# RP2040 register map
Vendor: Raspberry Pi; File version: 2025.06.15
CPU: CM0PLUS r0p1, little endian, 2 interrupt priority bits
Registers are 32-bit, read-write, no defined reset value unless marked. A register's access mark holds for its fields unless they carry their own. Offsets are from the block's base; [hi:lo] are bit positions; 'fields as' and 'values as' point back to an identical list; <NAME> marks a mode.

## I2C0 (part 1 of 2) — DW_apb_i2c address block List of configuration constants for the Synopsys I2C hardware (you may see references to these in I2C register header these are *fixed* values, set at hardware design time): IC_ULTRA_FAST_MODE ................ 0x0 IC_UFM_TBUF_CNT_DEFAULT ........... 0x8 IC_UFM_SCL_LOW_COUNT .............. 0x0008 IC_UFM_SCL_HIGH_COUNT ............. 0x0006 IC_TX_TL .......................... 0x0 IC_TX_CMD_BLOCK ................... 0x1 IC_HAS_DMA ........................ 0x1 IC_HAS_ASYNC_FIFO ................. 0x0 IC_SMBUS_ARP ...................... 0x0 IC_FIRST_DATA_BYTE_STATUS ......... 0x1 IC_INTR_IO ........................ 0x1 IC_MASTER_MODE .................... 0x1 IC_DEFAULT_ACK_GENERAL_CALL ....... 0x1 IC_INTR_POL ....................... 0x1 IC_OPTIONAL_SAR ................... 0x0 IC_DEFAULT_TAR_SLAVE_ADDR ......... 0x055 IC_DEFAULT_SLAVE_ADDR ............. 0x055 IC_DEFAULT_HS_SPKLEN .............. 0x1 IC_FS_SCL_HIGH_COUNT .............. 0x0006 IC_HS_SCL_LOW_COUNT ............... 0x0008 IC_DEVICE_ID_VALUE ................ 0x0 IC_10BITADDR_MASTER ............... 0x0 IC_CLK_FREQ_OPTIMIZATION .......... 0x0 IC_DEFAULT_FS_SPKLEN .............. 0x7 IC_ADD_ENCODED_PARAMS ............. 0x0 IC_DEFAULT_SDA_HOLD ............... 0x000001 IC_DEFAULT_SDA_SETUP .............. 0x64 IC_AVOID_RX_FIFO_FLUSH_ON_TX_ABRT . 0x0 IC_CLOCK_PERIOD ................... 100 IC_EMPTYFIFO_HOLD_MASTER_EN ....... 1 IC_RESTART_EN ..................... 0x1 IC_TX_CMD_BLOCK_DEFAULT ........... 0x0 IC_BUS_CLEAR_FEATURE .............. 0x0 IC_CAP_LOADING .................... 100 IC_FS_SCL_LOW_COUNT ............... 0x000d APB_DATA_WIDTH .................... 32 IC_SDA_STUCK_TIMEOUT_DEFAULT ...... 0xffffffff IC_SLV_DATA_NACK_ONLY ............. 0x1 IC_10BITADDR_SLAVE ................ 0x0 IC_CLK_TYPE ....................... 0x0 IC_SMBUS_UDID_MSB ................. 0x0 IC_SMBUS_SUSPEND_ALERT ............ 0x0 IC_HS_SCL_HIGH_COUNT .............. 0x0006 IC_SLV_RESTART_DET_EN ............. 0x1 IC_SMBUS .......................... 0x0 IC_OPTIONAL_SAR_DEFAULT ........... 0x0 IC_PERSISTANT_SLV_ADDR_DEFAULT .... 0x0 IC_USE_COUNTS ..................... 0x0 IC_RX_BUFFER_DEPTH ................ 16 IC_SCL_STUCK_TIMEOUT_DEFAULT ...... 0xffffffff IC_RX_FULL_HLD_BUS_EN ............. 0x1 IC_SLAVE_DISABLE .................. 0x1 IC_RX_TL .......................... 0x0 IC_DEVICE_ID ...................... 0x0 IC_HC_COUNT_VALUES ................ 0x0 I2C_DYNAMIC_TAR_UPDATE ............ 0 IC_SMBUS_CLK_LOW_MEXT_DEFAULT ..... 0xffffffff IC_SMBUS_CLK_LOW_SEXT_DEFAULT ..... 0xffffffff IC_HS_MASTER_CODE ................. 0x1 IC_SMBUS_RST_IDLE_CNT_DEFAULT ..... 0xffff IC_SMBUS_UDID_LSB_DEFAULT ......... 0xffffffff IC_SS_SCL_HIGH_COUNT .............. 0x0028 IC_SS_SCL_LOW_COUNT ............... 0x002f IC_MAX_SPEED_MODE ................. 0x2 IC_STAT_FOR_CLK_STRETCH ........... 0x0 IC_STOP_DET_IF_MASTER_ACTIVE ...... 0x0 IC_DEFAULT_UFM_SPKLEN ............. 0x1 IC_TX_BUFFER_DEPTH ................ 16
Base 0x40044000
Same registers: I2C1 0x40048000
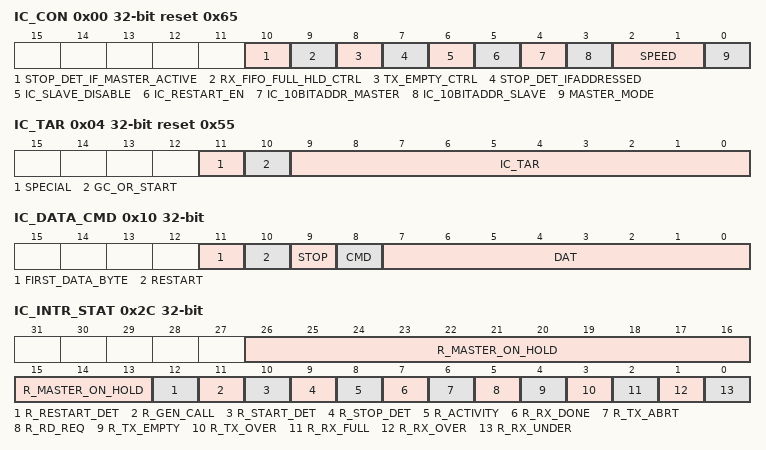
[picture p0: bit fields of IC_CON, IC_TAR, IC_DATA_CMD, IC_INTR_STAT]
0x00 IC_CON reset 0x65 (reset mask 0x0) — I2C Control Register. This register can be written only when the DW_apb_i2c is disabled, which corresponds to the IC_ENABLE[0] register being set to 0. Writes at other times have no effect. Read/Write Access: - bit 10 is read only. - bit 11 is read only - bit 16 is read only - bit 17 is read only - bits 18 and 19 are read only.
  [10] STOP_DET_IF_MASTER_ACTIVE ro — Master issues the STOP_DET interrupt irrespective of whether master is active or not
  [9] RX_FIFO_FULL_HLD_CTRL — This bit controls whether DW_apb_i2c should hold the bus when the Rx FIFO is physically full to its RX_BUFFER_DEPTH, as described in the IC_RX_FULL_HLD_BUS_EN parameter. Reset value: 0x0.
    0=DISABLED (Overflow when RX_FIFO is full); 1=ENABLED (Hold bus when RX_FIFO is full)
  [8] TX_EMPTY_CTRL — This bit controls the generation of the TX_EMPTY interrupt, as described in the IC_RAW_INTR_STAT register. Reset value: 0x0.
    0=DISABLED (Default behaviour of TX_EMPTY interrupt); 1=ENABLED (Controlled generation of TX_EMPTY interrupt)
  [7] STOP_DET_IFADDRESSED — In slave mode: - 1'b1: issues the STOP_DET interrupt only when it is addressed. - 1'b0: issues the STOP_DET irrespective of whether it's addressed or not. Reset value: 0x0 NOTE: During a general call address, this slave does not issue the STOP_DET interrupt if STOP_DET_IF_ADDRESSED = 1'b1, even if the slave responds to the general call address by generating ACK. The STOP_DET interrupt is generated only when the transmitted address matches the slave address (SAR).
    0=DISABLED (slave issues STOP_DET intr always); 1=ENABLED (slave issues STOP_DET intr only if addressed)
  [6] IC_SLAVE_DISABLE — This bit controls whether I2C has its slave disabled, which means once the presetn signal is applied, then this bit is set and the slave is disabled. If this bit is set (slave is disabled), DW_apb_i2c functions only as a master and does not perform any action that requires a slave. NOTE: Software should ensure that if this bit is written with 0, then bit 0 should also be written with a 0.
    0=SLAVE_ENABLED (Slave mode is enabled); 1=SLAVE_DISABLED (Slave mode is disabled)
  [5] IC_RESTART_EN — Determines whether RESTART conditions may be sent when acting as a master. Some older slaves do not support handling RESTART conditions however, RESTART conditions are used in several DW_apb_i2c operations. When RESTART is disabled, the master is prohibited from performing the following functions: - Sending a START BYTE - Performing any high-speed mode operation - High-speed mode operation - Performing direction changes in combined format mode - Performing a read operation with a 10-bit address By replacing RESTART condition followed by a STOP and a subsequent START condition, split operations are broken down into multiple DW_apb_i2c transfers. If the above operations are performed, it will result in setting bit 6 (TX_ABRT) of the IC_RAW_INTR_STAT register. Reset value: ENABLED
    0=DISABLED (Master restart disabled); 1=ENABLED (Master restart enabled)
  [4] IC_10BITADDR_MASTER — Controls whether the DW_apb_i2c starts its transfers in 7- or 10-bit addressing mode when acting as a master. - 0: 7-bit addressing - 1: 10-bit addressing
    0=ADDR_7BITS (Master 7Bit addressing mode); 1=ADDR_10BITS (Master 10Bit addressing mode)
  [3] IC_10BITADDR_SLAVE — When acting as a slave, this bit controls whether the DW_apb_i2c responds to 7- or 10-bit addresses. - 0: 7-bit addressing. The DW_apb_i2c ignores transactions that involve 10-bit addressing for 7-bit addressing, only the lower 7 bits of the IC_SAR register are compared. - 1: 10-bit addressing. The DW_apb_i2c responds to only 10-bit addressing transfers that match the full 10 bits of the IC_SAR register.
    0=ADDR_7BITS (Slave 7Bit addressing); 1=ADDR_10BITS (Slave 10Bit addressing)
  [2:1] SPEED — These bits control at which speed the DW_apb_i2c operates its setting is relevant only if one is operating the DW_apb_i2c in master mode. Hardware protects against illegal values being programmed by software. These bits must be programmed appropriately for slave mode also, as it is used to capture correct value of spike filter as per the speed mode. This register should be programmed only with a value in the range of 1 to IC_MAX_SPEED_MODE otherwise, hardware updates this register with the value of IC_MAX_SPEED_MODE. 1: standard mode (100 kbit/s) 2: fast mode (<=400 kbit/s) or fast mode plus (<=1000Kbit/s) 3: high speed mode (3.4 Mbit/s) Note: This field is not applicable when IC_ULTRA_FAST_MODE=1
    1=STANDARD (Standard Speed mode of operation); 2=FAST (Fast or Fast Plus mode of operation); 3=HIGH (High Speed mode of operation)
  [0] MASTER_MODE — This bit controls whether the DW_apb_i2c master is enabled. NOTE: Software should ensure that if this bit is written with '1' then bit 6 should also be written with a '1'.
    0=DISABLED (Master mode is disabled); 1=ENABLED (Master mode is enabled)
0x04 IC_TAR reset 0x55 (reset mask 0x0) — I2C Target Address Register This register is 12 bits wide, and bits 31:12 are reserved. This register can be written to only when IC_ENABLE[0] is set to 0. Note: If the software or application is aware that the DW_apb_i2c is not using the TAR address for the pending commands in the Tx FIFO, then it is possible to update the TAR address even while the Tx FIFO has entries (IC_STATUS[2]= 0). - It is not necessary to perform any write to this register if DW_apb_i2c is enabled as an I2C slave only.
  [11] SPECIAL — This bit indicates whether software performs a Device-ID or General Call or START BYTE command. - 0: ignore bit 10 GC_OR_START and use IC_TAR normally - 1: perform special I2C command as specified in Device_ID or GC_OR_START bit Reset value: 0x0
    0=DISABLED (Disables programming of GENERAL_CALL or START_BYTE transmission); 1=ENABLED (Enables programming of GENERAL_CALL or START_BYTE transmission)
  [10] GC_OR_START — If bit 11 (SPECIAL) is set to 1 and bit 13(Device-ID) is set to 0, then this bit indicates whether a General Call or START byte command is to be performed by the DW_apb_i2c. - 0: General Call Address - after issuing a General Call, only writes may be performed. Attempting to issue a read command results in setting bit 6 (TX_ABRT) of the IC_RAW_INTR_STAT register. The DW_apb_i2c remains in General Call mode until the SPECIAL bit value (bit 11) is cleared. - 1: START BYTE Reset value: 0x0
    0=GENERAL_CALL (GENERAL_CALL byte transmission); 1=START_BYTE (START byte transmission)
  [9:0] IC_TAR — This is the target address for any master transaction. When transmitting a General Call, these bits are ignored. To generate a START BYTE, the CPU needs to write only once into these bits. If the IC_TAR and IC_SAR are the same, loopback exists but the FIFOs are shared between master and slave, so full loopback is not feasible. Only one direction loopback mode is supported (simplex), not duplex. A master cannot transmit to itself it can transmit to only a slave.
0x08 IC_SAR reset 0x55 (reset mask 0x0) — I2C Slave Address Register
  [9:0] IC_SAR — The IC_SAR holds the slave address when the I2C is operating as a slave. For 7-bit addressing, only IC_SAR[6:0] is used. This register can be written only when the I2C interface is disabled, which corresponds to the IC_ENABLE[0] register being set to 0. Writes at other times have no effect. Note: The default values cannot be any of the reserved address locations: that is, 0x00 to 0x07, or 0x78 to 0x7f. The correct operation of the device is not guaranteed if you program the IC_SAR or IC_TAR to a reserved value. Refer to <<table_I2C_firstbyte_bit_defs>> for a complete list of these reserved values.
0x10 IC_DATA_CMD — I2C Rx/Tx Data Buffer and Command Register this is the register the CPU writes to when filling the TX FIFO and the CPU reads from when retrieving bytes from RX FIFO. The size of the register changes as follows: Write: - 11 bits when IC_EMPTYFIFO_HOLD_MASTER_EN=1 - 9 bits when IC_EMPTYFIFO_HOLD_MASTER_EN=0 Read: - 12 bits when IC_FIRST_DATA_BYTE_STATUS = 1 - 8 bits when IC_FIRST_DATA_BYTE_STATUS = 0 Note: In order for the DW_apb_i2c to continue acknowledging reads, a read command should be written for every byte that is to be received otherwise the DW_apb_i2c will stop acknowledging.
  [11] FIRST_DATA_BYTE ro — Indicates the first data byte received after the address phase for receive transfer in Master receiver or Slave receiver mode. Reset value : 0x0 NOTE: In case of APB_DATA_WIDTH=8, 1. The user has to perform two APB Reads to IC_DATA_CMD in order to get status on 11 bit. 2. In order to read the 11 bit, the user has to perform the first data byte read [7:0] (offset 0x10) and then perform the second read [15:8] (offset 0x11) in order to know the status of 11 bit (whether the data received in previous read is a first data byte or not). 3. The 11th bit is an optional read field, user can ignore 2nd byte read [15:8] (offset 0x11) if not interested in FIRST_DATA_BYTE status.
    0=INACTIVE (Sequential data byte received); 1=ACTIVE (Non sequential data byte received)
  [10] RESTART write-clears — This bit controls whether a RESTART is issued before the byte is sent or received. 1 - If IC_RESTART_EN is 1, a RESTART is issued before the data is sent/received (according to the value of CMD), regardless of whether or not the transfer direction is changing from the previous command if IC_RESTART_EN is 0, a STOP followed by a START is issued instead. 0 - If IC_RESTART_EN is 1, a RESTART is issued only if the transfer direction is changing from the previous command if IC_RESTART_EN is 0, a STOP followed by a START is issued instead. Reset value: 0x0
    0=DISABLE (Don't Issue RESTART before this command); 1=ENABLE (Issue RESTART before this command)
  [9] STOP write-clears — This bit controls whether a STOP is issued after the byte is sent or received. - 1 - STOP is issued after this byte, regardless of whether or not the Tx FIFO is empty. If the Tx FIFO is not empty, the master immediately tries to start a new transfer by issuing a START and arbitrating for the bus. - 0 - STOP is not issued after this byte, regardless of whether or not the Tx FIFO is empty. If the Tx FIFO is not empty, the master continues the current transfer by sending/receiving data bytes according to the value of the CMD bit. If the Tx FIFO is empty, the master holds the SCL line low and stalls the bus until a new command is available in the Tx FIFO. Reset value: 0x0
    0=DISABLE (Don't Issue STOP after this command); 1=ENABLE (Issue STOP after this command)
  [8] CMD write-clears — This bit controls whether a read or a write is performed. This bit does not control the direction when the DW_apb_i2con acts as a slave. It controls only the direction when it acts as a master. When a command is entered in the TX FIFO, this bit distinguishes the write and read commands. In slave-receiver mode, this bit is a 'don't care' because writes to this register are not required. In slave-transmitter mode, a '0' indicates that the data in IC_DATA_CMD is to be transmitted. When programming this bit, you should remember the following: attempting to perform a read operation after a General Call command has been sent results in a TX_ABRT interrupt (bit 6 of the IC_RAW_INTR_STAT register), unless bit 11 (SPECIAL) in the IC_TAR register has been cleared. If a '1' is written to this bit after receiving a RD_REQ interrupt, then a TX_ABRT interrupt occurs. Reset value: 0x0
    0=WRITE (Master Write Command); 1=READ (Master Read Command)
  [7:0] DAT — This register contains the data to be transmitted or received on the I2C bus. If you are writing to this register and want to perform a read, bits 7:0 (DAT) are ignored by the DW_apb_i2c. However, when you read this register, these bits return the value of data received on the DW_apb_i2c interface. Reset value: 0x0
0x14 IC_SS_SCL_HCNT reset 0x28 (reset mask 0x0) — Standard Speed I2C Clock SCL High Count Register
  [15:0] IC_SS_SCL_HCNT — This register must be set before any I2C bus transaction can take place to ensure proper I/O timing. This register sets the SCL clock high-period count for standard speed. For more information, refer to 'IC_CLK Frequency Configuration'. This register can be written only when the I2C interface is disabled which corresponds to the IC_ENABLE[0] register being set to 0. Writes at other times have no effect. The minimum valid value is 6 hardware prevents values less than this being written, and if attempted results in 6 being set. For designs with APB_DATA_WIDTH = 8, the order of programming is important to ensure the correct operation of the DW_apb_i2c. The lower byte must be programmed first. Then the upper byte is programmed. NOTE: This register must not be programmed to a value higher than 65525, because DW_apb_i2c uses a 16-bit counter to flag an I2C bus idle condition when this counter reaches a value of IC_SS_SCL_HCNT + 10.
0x18 IC_SS_SCL_LCNT reset 0x2F (reset mask 0x0) — Standard Speed I2C Clock SCL Low Count Register
  [15:0] IC_SS_SCL_LCNT — This register must be set before any I2C bus transaction can take place to ensure proper I/O timing. This register sets the SCL clock low period count for standard speed. For more information, refer to 'IC_CLK Frequency Configuration' This register can be written only when the I2C interface is disabled which corresponds to the IC_ENABLE[0] register being set to 0. Writes at other times have no effect. The minimum valid value is 8 hardware prevents values less than this being written, and if attempted, results in 8 being set. For designs with APB_DATA_WIDTH = 8, the order of programming is important to ensure the correct operation of DW_apb_i2c. The lower byte must be programmed first, and then the upper byte is programmed.
0x1C IC_FS_SCL_HCNT reset 0x6 (reset mask 0x0) — Fast Mode or Fast Mode Plus I2C Clock SCL High Count Register
  [15:0] IC_FS_SCL_HCNT — This register must be set before any I2C bus transaction can take place to ensure proper I/O timing. This register sets the SCL clock high-period count for fast mode or fast mode plus. It is used in high-speed mode to send the Master Code and START BYTE or General CALL. For more information, refer to 'IC_CLK Frequency Configuration'. This register goes away and becomes read-only returning 0s if IC_MAX_SPEED_MODE = standard. This register can be written only when the I2C interface is disabled, which corresponds to the IC_ENABLE[0] register being set to 0. Writes at other times have no effect. The minimum valid value is 6 hardware prevents values less than this being written, and if attempted results in 6 being set. For designs with APB_DATA_WIDTH == 8 the order of programming is important to ensure the correct operation of the DW_apb_i2c. The lower byte must be programmed first. Then the upper byte is programmed.
0x20 IC_FS_SCL_LCNT reset 0xD (reset mask 0x0) — Fast Mode or Fast Mode Plus I2C Clock SCL Low Count Register
  [15:0] IC_FS_SCL_LCNT — This register must be set before any I2C bus transaction can take place to ensure proper I/O timing. This register sets the SCL clock low period count for fast speed. It is used in high-speed mode to send the Master Code and START BYTE or General CALL. For more information, refer to 'IC_CLK Frequency Configuration'. This register goes away and becomes read-only returning 0s if IC_MAX_SPEED_MODE = standard. This register can be written only when the I2C interface is disabled, which corresponds to the IC_ENABLE[0] register being set to 0. Writes at other times have no effect. The minimum valid value is 8 hardware prevents values less than this being written, and if attempted results in 8 being set. For designs with APB_DATA_WIDTH = 8 the order of programming is important to ensure the correct operation of the DW_apb_i2c. The lower byte must be programmed first. Then the upper byte is programmed. If the value is less than 8 then the count value gets changed to 8.
0x2C IC_INTR_STAT — I2C Interrupt Status Register Each bit in this register has a corresponding mask bit in the IC_INTR_MASK register. These bits are cleared by reading the matching interrupt clear register. The unmasked raw versions of these bits are available in the IC_RAW_INTR_STAT register.
  [26:13] R_MASTER_ON_HOLD ro — See IC_RAW_INTR_STAT for a detailed description of R_MASTER_ON_HOLD bit. . Reset value: 0x0
    0=INACTIVE (R_MASTER_ON_HOLD interrupt is inactive); 1=ACTIVE (R_MASTER_ON_HOLD interrupt is active)
  [12] R_RESTART_DET ro — See IC_RAW_INTR_STAT for a detailed description of R_RESTART_DET bit. Reset value: 0x0
    0=INACTIVE (R_RESTART_DET interrupt is inactive); 1=ACTIVE (R_RESTART_DET interrupt is active)
  [11] R_GEN_CALL ro — See IC_RAW_INTR_STAT for a detailed description of R_GEN_CALL bit. Reset value: 0x0
    0=INACTIVE (R_GEN_CALL interrupt is inactive); 1=ACTIVE (R_GEN_CALL interrupt is active)
  [10] R_START_DET ro — See IC_RAW_INTR_STAT for a detailed description of R_START_DET bit. Reset value: 0x0
    0=INACTIVE (R_START_DET interrupt is inactive); 1=ACTIVE (R_START_DET interrupt is active)
  [9] R_STOP_DET ro — See IC_RAW_INTR_STAT for a detailed description of R_STOP_DET bit. Reset value: 0x0
    0=INACTIVE (R_STOP_DET interrupt is inactive); 1=ACTIVE (R_STOP_DET interrupt is active)
  [8] R_ACTIVITY ro — See IC_RAW_INTR_STAT for a detailed description of R_ACTIVITY bit. Reset value: 0x0
    0=INACTIVE (R_ACTIVITY interrupt is inactive); 1=ACTIVE (R_ACTIVITY interrupt is active)
  [7] R_RX_DONE ro — See IC_RAW_INTR_STAT for a detailed description of R_RX_DONE bit. Reset value: 0x0
    0=INACTIVE (R_RX_DONE interrupt is inactive); 1=ACTIVE (R_RX_DONE interrupt is active)
  [6] R_TX_ABRT ro — See IC_RAW_INTR_STAT for a detailed description of R_TX_ABRT bit. Reset value: 0x0
    0=INACTIVE (R_TX_ABRT interrupt is inactive); 1=ACTIVE (R_TX_ABRT interrupt is active)
  [5] R_RD_REQ ro — See IC_RAW_INTR_STAT for a detailed description of R_RD_REQ bit. Reset value: 0x0
    0=INACTIVE (R_RD_REQ interrupt is inactive); 1=ACTIVE (R_RD_REQ interrupt is active)
  [4] R_TX_EMPTY ro — See IC_RAW_INTR_STAT for a detailed description of R_TX_EMPTY bit. Reset value: 0x0
    0=INACTIVE (R_TX_EMPTY interrupt is inactive); 1=ACTIVE (R_TX_EMPTY interrupt is active)
  [3] R_TX_OVER ro — See IC_RAW_INTR_STAT for a detailed description of R_TX_OVER bit. Reset value: 0x0
    0=INACTIVE (R_TX_OVER interrupt is inactive); 1=ACTIVE (R_TX_OVER interrupt is active)
  [2] R_RX_FULL ro — See IC_RAW_INTR_STAT for a detailed description of R_RX_FULL bit. Reset value: 0x0
    0=INACTIVE (R_RX_FULL interrupt is inactive); 1=ACTIVE (R_RX_FULL interrupt is active)
  [1] R_RX_OVER ro — See IC_RAW_INTR_STAT for a detailed description of R_RX_OVER bit. Reset value: 0x0
    0=INACTIVE (R_RX_OVER interrupt is inactive); 1=ACTIVE (R_RX_OVER interrupt is active)
  [0] R_RX_UNDER ro — See IC_RAW_INTR_STAT for a detailed description of R_RX_UNDER bit. Reset value: 0x0
    0=INACTIVE (RX_UNDER interrupt is inactive); 1=ACTIVE (RX_UNDER interrupt is active)
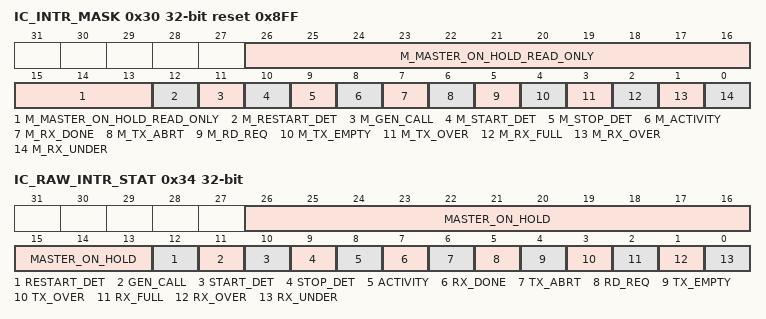
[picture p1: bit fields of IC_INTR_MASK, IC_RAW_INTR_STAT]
0x30 IC_INTR_MASK reset 0x8FF (reset mask 0x0) — I2C Interrupt Mask Register. These bits mask their corresponding interrupt status bits. This register is active low a value of 0 masks the interrupt, whereas a value of 1 unmasks the interrupt.
  [26:13] M_MASTER_ON_HOLD_READ_ONLY ro — This M_MASTER_ON_HOLD_read_only bit masks the R_MASTER_ON_HOLD interrupt in IC_INTR_STAT register. . Reset value: 0x0
    0=ENABLED (MASTER_ON_HOLD interrupt is masked); 1=DISABLED (MASTER_ON_HOLD interrupt is unmasked)
  [12] M_RESTART_DET — This bit masks the R_RESTART_DET interrupt in IC_INTR_STAT register. Reset value: 0x0
    0=ENABLED (RESTART_DET interrupt is masked); 1=DISABLED (RESTART_DET interrupt is unmasked)
  [11] M_GEN_CALL — This bit masks the R_GEN_CALL interrupt in IC_INTR_STAT register. Reset value: 0x1
    0=ENABLED (GEN_CALL interrupt is masked); 1=DISABLED (GEN_CALL interrupt is unmasked)
  [10] M_START_DET — This bit masks the R_START_DET interrupt in IC_INTR_STAT register. Reset value: 0x0
    0=ENABLED (START_DET interrupt is masked); 1=DISABLED (START_DET interrupt is unmasked)
  [9] M_STOP_DET — This bit masks the R_STOP_DET interrupt in IC_INTR_STAT register. Reset value: 0x0
    0=ENABLED (STOP_DET interrupt is masked); 1=DISABLED (STOP_DET interrupt is unmasked)
  [8] M_ACTIVITY — This bit masks the R_ACTIVITY interrupt in IC_INTR_STAT register. Reset value: 0x0
    0=ENABLED (ACTIVITY interrupt is masked); 1=DISABLED (ACTIVITY interrupt is unmasked)
  [7] M_RX_DONE — This bit masks the R_RX_DONE interrupt in IC_INTR_STAT register. Reset value: 0x1
    0=ENABLED (RX_DONE interrupt is masked); 1=DISABLED (RX_DONE interrupt is unmasked)
  [6] M_TX_ABRT — This bit masks the R_TX_ABRT interrupt in IC_INTR_STAT register. Reset value: 0x1
    0=ENABLED (TX_ABORT interrupt is masked); 1=DISABLED (TX_ABORT interrupt is unmasked)
  [5] M_RD_REQ — This bit masks the R_RD_REQ interrupt in IC_INTR_STAT register. Reset value: 0x1
    0=ENABLED (RD_REQ interrupt is masked); 1=DISABLED (RD_REQ interrupt is unmasked)
  [4] M_TX_EMPTY — This bit masks the R_TX_EMPTY interrupt in IC_INTR_STAT register. Reset value: 0x1
    0=ENABLED (TX_EMPTY interrupt is masked); 1=DISABLED (TX_EMPTY interrupt is unmasked)
  [3] M_TX_OVER — This bit masks the R_TX_OVER interrupt in IC_INTR_STAT register. Reset value: 0x1
    0=ENABLED (TX_OVER interrupt is masked); 1=DISABLED (TX_OVER interrupt is unmasked)
  [2] M_RX_FULL — This bit masks the R_RX_FULL interrupt in IC_INTR_STAT register. Reset value: 0x1
    0=ENABLED (RX_FULL interrupt is masked); 1=DISABLED (RX_FULL interrupt is unmasked)
  [1] M_RX_OVER — This bit masks the R_RX_OVER interrupt in IC_INTR_STAT register. Reset value: 0x1
    0=ENABLED (RX_OVER interrupt is masked); 1=DISABLED (RX_OVER interrupt is unmasked)
  [0] M_RX_UNDER — This bit masks the R_RX_UNDER interrupt in IC_INTR_STAT register. Reset value: 0x1
    0=ENABLED (RX_UNDER interrupt is masked); 1=DISABLED (RX_UNDER interrupt is unmasked)
0x34 IC_RAW_INTR_STAT — I2C Raw Interrupt Status Register Unlike the IC_INTR_STAT register, these bits are not masked so they always show the true status of the DW_apb_i2c.
  [26:13] MASTER_ON_HOLD ro — Indicates whether master is holding the bus and TX FIFO is empty. Enabled only when I2C_DYNAMIC_TAR_UPDATE=1 and IC_EMPTYFIFO_HOLD_MASTER_EN=1. . Reset value: 0x0
    0=INACTIVE (MASTER_ON_HOLD interrupt is inactive); 1=ACTIVE (MASTER_ON_HOLD interrupt is active)
  [12] RESTART_DET ro — Indicates whether a RESTART condition has occurred on the I2C interface when DW_apb_i2c is operating in Slave mode and the slave is being addressed. Enabled only when IC_SLV_RESTART_DET_EN=1. Note: However, in high-speed mode or during a START BYTE transfer, the RESTART comes before the address field as per the I2C protocol. In this case, the slave is not the addressed slave when the RESTART is issued, therefore DW_apb_i2c does not generate the RESTART_DET interrupt. Reset value: 0x0
    0=INACTIVE (RESTART_DET interrupt is inactive); 1=ACTIVE (RESTART_DET interrupt is active)
  [11] GEN_CALL ro — Set only when a General Call address is received and it is acknowledged. It stays set until it is cleared either by disabling DW_apb_i2c or when the CPU reads bit 0 of the IC_CLR_GEN_CALL register. DW_apb_i2c stores the received data in the Rx buffer. Reset value: 0x0
    0=INACTIVE (GEN_CALL interrupt is inactive); 1=ACTIVE (GEN_CALL interrupt is active)
  [10] START_DET ro — Indicates whether a START or RESTART condition has occurred on the I2C interface regardless of whether DW_apb_i2c is operating in slave or master mode. Reset value: 0x0
    0=INACTIVE (START_DET interrupt is inactive); 1=ACTIVE (START_DET interrupt is active)
  [9] STOP_DET ro — Indicates whether a STOP condition has occurred on the I2C interface regardless of whether DW_apb_i2c is operating in slave or master mode. In Slave Mode: - If IC_CON[7]=1'b1 (STOP_DET_IFADDRESSED), the STOP_DET interrupt will be issued only if slave is addressed. Note: During a general call address, this slave does not issue a STOP_DET interrupt if STOP_DET_IF_ADDRESSED=1'b1, even if the slave responds to the general call address by generating ACK. The STOP_DET interrupt is generated only when the transmitted address matches the slave address (SAR). - If IC_CON[7]=1'b0 (STOP_DET_IFADDRESSED), the STOP_DET interrupt is issued irrespective of whether it is being addressed. In Master Mode: - If IC_CON[10]=1'b1 (STOP_DET_IF_MASTER_ACTIVE),the STOP_DET interrupt will be issued only if Master is active. - If IC_CON[10]=1'b0 (STOP_DET_IFADDRESSED),the STOP_DET interrupt will be issued irrespective of whether master is active or not. Reset value: 0x0
    0=INACTIVE (STOP_DET interrupt is inactive); 1=ACTIVE (STOP_DET interrupt is active)
  [8] ACTIVITY ro — This bit captures DW_apb_i2c activity and stays set until it is cleared. There are four ways to clear it: - Disabling the DW_apb_i2c - Reading the IC_CLR_ACTIVITY register - Reading the IC_CLR_INTR register - System reset Once this bit is set, it stays set unless one of the four methods is used to clear it. Even if the DW_apb_i2c module is idle, this bit remains set until cleared, indicating that there was activity on the bus. Reset value: 0x0
    0=INACTIVE (RAW_INTR_ACTIVITY interrupt is inactive); 1=ACTIVE (RAW_INTR_ACTIVITY interrupt is active)
  [7] RX_DONE ro — When the DW_apb_i2c is acting as a slave-transmitter, this bit is set to 1 if the master does not acknowledge a transmitted byte. This occurs on the last byte of the transmission, indicating that the transmission is done. Reset value: 0x0
    0=INACTIVE (RX_DONE interrupt is inactive); 1=ACTIVE (RX_DONE interrupt is active)
  [6] TX_ABRT ro — This bit indicates if DW_apb_i2c, as an I2C transmitter, is unable to complete the intended actions on the contents of the transmit FIFO. This situation can occur both as an I2C master or an I2C slave, and is referred to as a 'transmit abort'. When this bit is set to 1, the IC_TX_ABRT_SOURCE register indicates the reason why the transmit abort takes places. Note: The DW_apb_i2c flushes/resets/empties the TX_FIFO and RX_FIFO whenever there is a transmit abort caused by any of the events tracked by the IC_TX_ABRT_SOURCE register. The FIFOs remains in this flushed state until the register IC_CLR_TX_ABRT is read. Once this read is performed, the Tx FIFO is then ready to accept more data bytes from the APB interface. Reset value: 0x0
    0=INACTIVE (TX_ABRT interrupt is inactive); 1=ACTIVE (TX_ABRT interrupt is active)
  [5] RD_REQ ro — This bit is set to 1 when DW_apb_i2c is acting as a slave and another I2C master is attempting to read data from DW_apb_i2c. The DW_apb_i2c holds the I2C bus in a wait state (SCL=0) until this interrupt is serviced, which means that the slave has been addressed by a remote master that is asking for data to be transferred. The processor must respond to this interrupt and then write the requested data to the IC_DATA_CMD register. This bit is set to 0 just after the processor reads the IC_CLR_RD_REQ register. Reset value: 0x0
    0=INACTIVE (RD_REQ interrupt is inactive); 1=ACTIVE (RD_REQ interrupt is active)
  [4] TX_EMPTY ro — The behavior of the TX_EMPTY interrupt status differs based on the TX_EMPTY_CTRL selection in the IC_CON register. - When TX_EMPTY_CTRL = 0: This bit is set to 1 when the transmit buffer is at or below the threshold value set in the IC_TX_TL register. - When TX_EMPTY_CTRL = 1: This bit is set to 1 when the transmit buffer is at or below the threshold value set in the IC_TX_TL register and the transmission of the address/data from the internal shift register for the most recently popped command is completed. It is automatically cleared by hardware when the buffer level goes above the threshold. When IC_ENABLE[0] is set to 0, the TX FIFO is flushed and held in reset. There the TX FIFO looks like it has no data within it, so this bit is set to 1, provided there is activity in the master or slave state machines. When there is no longer any activity, then with ic_en=0, this bit is set to 0. Reset value: 0x0.
    0=INACTIVE (TX_EMPTY interrupt is inactive); 1=ACTIVE (TX_EMPTY interrupt is active)
  [3] TX_OVER ro — Set during transmit if the transmit buffer is filled to IC_TX_BUFFER_DEPTH and the processor attempts to issue another I2C command by writing to the IC_DATA_CMD register. When the module is disabled, this bit keeps its level until the master or slave state machines go into idle, and when ic_en goes to 0, this interrupt is cleared. Reset value: 0x0
    0=INACTIVE (TX_OVER interrupt is inactive); 1=ACTIVE (TX_OVER interrupt is active)
  [2] RX_FULL ro — Set when the receive buffer reaches or goes above the RX_TL threshold in the IC_RX_TL register. It is automatically cleared by hardware when buffer level goes below the threshold. If the module is disabled (IC_ENABLE[0]=0), the RX FIFO is flushed and held in reset therefore the RX FIFO is not full. So this bit is cleared once the IC_ENABLE bit 0 is programmed with a 0, regardless of the activity that continues. Reset value: 0x0
    0=INACTIVE (RX_FULL interrupt is inactive); 1=ACTIVE (RX_FULL interrupt is active)
  [1] RX_OVER ro — Set if the receive buffer is completely filled to IC_RX_BUFFER_DEPTH and an additional byte is received from an external I2C device. The DW_apb_i2c acknowledges this, but any data bytes received after the FIFO is full are lost. If the module is disabled (IC_ENABLE[0]=0), this bit keeps its level until the master or slave state machines go into idle, and when ic_en goes to 0, this interrupt is cleared. Note: If bit 9 of the IC_CON register (RX_FIFO_FULL_HLD_CTRL) is programmed to HIGH, then the RX_OVER interrupt never occurs, because the Rx FIFO never overflows. Reset value: 0x0
    0=INACTIVE (RX_OVER interrupt is inactive); 1=ACTIVE (RX_OVER interrupt is active)
  [0] RX_UNDER ro — Set if the processor attempts to read the receive buffer when it is empty by reading from the IC_DATA_CMD register. If the module is disabled (IC_ENABLE[0]=0), this bit keeps its level until the master or slave state machines go into idle, and when ic_en goes to 0, this interrupt is cleared. Reset value: 0x0
    values as IC_INTR_STAT.R_RX_UNDER
